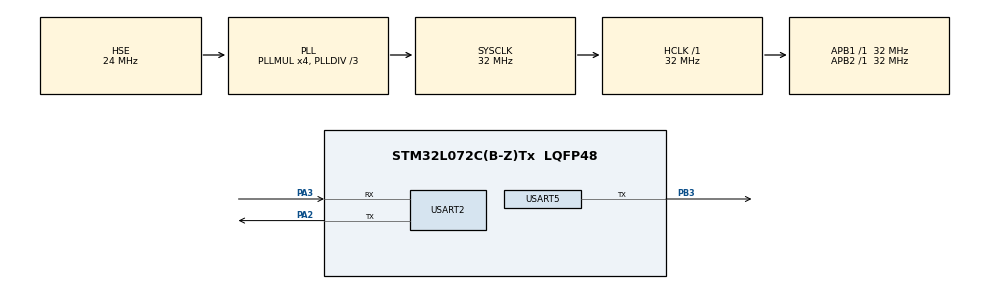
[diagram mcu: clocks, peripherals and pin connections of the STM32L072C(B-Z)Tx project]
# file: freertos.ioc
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Dma.Request0=USART2_RX
Dma.Request1=USART2_TX
Dma.Request2=USART5_TX
Dma.USART2_RX.0.Direction=DMA_PERIPH_TO_MEMORY
Dma.USART2_RX.0.Instance=DMA1_Channel5
Dma.USART2_RX.0.MemDataAlignment=DMA_MDATAALIGN_BYTE
Dma.USART2_RX.0.MemInc=DMA_MINC_ENABLE
Dma.USART2_RX.0.Mode=DMA_CIRCULAR
Dma.USART2_RX.0.PeriphDataAlignment=DMA_PDATAALIGN_BYTE
Dma.USART2_RX.0.PeriphInc=DMA_PINC_DISABLE
Dma.USART2_RX.0.Priority=DMA_PRIORITY_LOW
Dma.USART2_TX.1.Direction=DMA_MEMORY_TO_PERIPH
Dma.USART2_TX.1.Instance=DMA1_Channel4
Dma.USART2_TX.1.MemDataAlignment=DMA_MDATAALIGN_BYTE
Dma.USART2_TX.1.MemInc=DMA_MINC_ENABLE
Dma.USART2_TX.1.Mode=DMA_NORMAL
Dma.USART2_TX.1.PeriphDataAlignment=DMA_PDATAALIGN_BYTE
Dma.USART2_TX.1.PeriphInc=DMA_PINC_DISABLE
Dma.USART2_TX.1.Priority=DMA_PRIORITY_LOW
Dma.USART5_TX.2.Direction=DMA_MEMORY_TO_PERIPH
Dma.USART5_TX.2.Instance=DMA1_Channel3
Dma.USART5_TX.2.MemDataAlignment=DMA_MDATAALIGN_BYTE
Dma.USART5_TX.2.MemInc=DMA_MINC_ENABLE
Dma.USART5_TX.2.Mode=DMA_NORMAL
Dma.USART5_TX.2.PeriphDataAlignment=DMA_PDATAALIGN_BYTE
Dma.USART5_TX.2.PeriphInc=DMA_PINC_DISABLE
Dma.USART5_TX.2.Priority=DMA_PRIORITY_LOW
FREERTOS.Tasks01=defaultTask,24,128,StartDefaultTask,Default,NULL,Dynamic,NULL,NULL;umodemTask,24,256,StartUmodemTask,Default,NULL,Dynamic,NULL,NULL
FREERTOS.configGENERATE_RUN_TIME_STATS=1
FREERTOS.configRECORD_STACK_HIGH_ADDRESS=1
FREERTOS.configTOTAL_HEAP_SIZE=8192
Mcu.Family=STM32L0
Mcu.Name=STM32L072C(B-Z)Tx
Mcu.Package=LQFP48
NVIC.DMA1_Channel2_3_IRQn=true\:3\:0\:false\:false\:true\:true\:false\:true\:true
NVIC.DMA1_Channel4_5_6_7_IRQn=true\:3\:0\:false\:false\:true\:true\:false\:true\:true
NVIC.TIM2_IRQn=true\:3\:0\:false\:false\:true\:false\:false\:true\:true
NVIC.TimeBase=TIM2_IRQn
NVIC.TimeBaseIP=TIM2
NVIC.USART2_IRQn=true\:3\:0\:false\:false\:true\:true\:false\:true\:true
NVIC.USART4_5_IRQn=true\:3\:0\:false\:false\:true\:true\:true\:true\:true
PA2.Mode=Asynchronous
PA2.Signal=USART2_TX
PA3.Mode=Asynchronous
PA3.Signal=USART2_RX
PB3.Mode=Half_duplex(single_wire_mode)
PB3.Signal=USART5_TX
PH0-OSC_IN.Mode=HSE-External-Oscillator
PH0-OSC_IN.Signal=RCC_OSC_IN
PH1-OSC_OUT.Mode=HSE-External-Oscillator
PH1-OSC_OUT.Signal=RCC_OSC_OUT
ProjectManager.HeapSize=0x200
ProjectManager.StackSize=0x400
ProjectManager.TargetToolchain=CMake
RCC.AHBFreq_Value=32000000
RCC.APB1Freq_Value=32000000
RCC.APB1TimFreq_Value=32000000
RCC.APB2Freq_Value=32000000
RCC.APB2TimFreq_Value=32000000
RCC.HCLKFreq_Value=32000000
RCC.HSE_VALUE=24000000
RCC.HSI16_VALUE=16000000
RCC.HSI48_VALUE=48000000
RCC.HSI_VALUE=16000000
RCC.LSE_VALUE=32768
RCC.MSI_VALUE=2097000
RCC.PLLDIV=RCC_PLLDIV_3
RCC.PLLMUL=RCC_PLLMUL_4
RCC.PLLSourceVirtual=RCC_PLLSOURCE_HSE
RCC.SYSCLKFreq_VALUE=32000000
RCC.SYSCLKSource=RCC_SYSCLKSOURCE_PLLCLK
RCC.VCOOutputFreq_Value=96000000
USART2.VirtualMode-Asynchronous=VM_ASYNC
USART5.Mode=MODE_TX
USART5.VirtualMode-Half_duplex(single_wire_mode)=VM_ASYNC
VP_FREERTOS_VS_CMSIS_V2.Mode=CMSIS_V2
VP_SYS_VS_tim2.Mode=TIM2
board=custom

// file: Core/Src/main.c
/* USER CODE BEGIN Header */
/**
 ******************************************************************************
 * @file           : main.c
 * @brief          : Main program body
 ******************************************************************************
 * @attention
 *
 * Copyright (c) 2025 STMicroelectronics.
 * All rights reserved.
 *
 * This software is licensed under terms that can be found in the LICENSE file
 * in the root directory of this software component.
 * If no LICENSE file comes with this software, it is provided AS-IS.
 *
 ******************************************************************************
 */
/* USER CODE END Header */
#include "main.h"
#include "cmsis_os.h"

/* USER CODE BEGIN Includes */
#include <stdio.h>
#include <string.h>
#include <stdlib.h>

#include "umodem.h"
#include "umodem_sock.h"
/* USER CODE END Includes */

UART_HandleTypeDef huart2;
UART_HandleTypeDef huart5;
DMA_HandleTypeDef hdma_usart2_rx;
DMA_HandleTypeDef hdma_usart2_tx;
DMA_HandleTypeDef hdma_usart5_tx;

/* Definitions for defaultTask */
osThreadId_t defaultTaskHandle;
const osThreadAttr_t defaultTask_attributes = {
  .name = "defaultTask",
  .stack_size = 128 * 4,
  .priority = (osPriority_t) osPriorityNormal,
};
/* Definitions for umodemTask */
osThreadId_t umodemTaskHandle;
const osThreadAttr_t umodemTask_attributes = {
  .name = "umodemTask",
  .stack_size = 256 * 4,
  .priority = (osPriority_t) osPriorityNormal,
};

void SystemClock_Config(void);
static void MX_GPIO_Init(void);
static void MX_DMA_Init(void);
static void MX_USART2_UART_Init(void);
static void MX_USART5_UART_Init(void);
void StartDefaultTask(void *argument);
void StartUmodemTask(void *argument);

/* USER CODE BEGIN 0 */
static osSemaphoreId_t tx5_sem = NULL;
void HAL_UART5_TxCpltCallback(UART_HandleTypeDef *huart)
{
  if (huart->Instance == USART5)
    osSemaphoreRelease(tx5_sem); /* Release the semaphore after the DMA transfer is complete */
}

#ifdef __GNUC__
/* With GCC/RAISONANCE, small printf (option LD Linker->Libraries->Small printf
   set to 'Yes') calls __io_putchar() */
#define PUTCHAR_PROTOTYPE int __io_putchar(int ch)
#else
#define PUTCHAR_PROTOTYPE int fputc(int ch, FILE *f)
#endif /* __GNUC__ */

PUTCHAR_PROTOTYPE
{
  /* Place your implementation of fputc here */
  /* e.g. write a character to the USART5 and Loop until the end of transmission */
  osSemaphoreAcquire(tx5_sem, osWaitForever);
  HAL_UART_Transmit_DMA(&huart5, (uint8_t *)&ch, 1);

  return ch;
}
/* USER CODE END 0 */

int main(void)
{

  /* MCU Configuration--------------------------------------------------------*/

  /* Reset of all peripherals, Initializes the Flash interface and the Systick. */
  HAL_Init();

  /* Configure the system clock */
  SystemClock_Config();

  /* Initialize all configured peripherals */
  MX_GPIO_Init();
  MX_DMA_Init();
  MX_USART2_UART_Init();
  MX_USART5_UART_Init();

  /* Init scheduler */
  osKernelInitialize();

  /* Create the thread(s) */
  /* creation of defaultTask */
  defaultTaskHandle = osThreadNew(StartDefaultTask, NULL, &defaultTask_attributes);

  /* creation of umodemTask */
  umodemTaskHandle = osThreadNew(StartUmodemTask, NULL, &umodemTask_attributes);

  /* Start scheduler */
  osKernelStart();

  /* We should never get here as control is now taken by the scheduler */

  /* Infinite loop */
  while (1)
  {

  }
}

void SystemClock_Config(void)
{
  RCC_OscInitTypeDef RCC_OscInitStruct = {0};
  RCC_ClkInitTypeDef RCC_ClkInitStruct = {0};
  RCC_PeriphCLKInitTypeDef PeriphClkInit = {0};

  /** Configure the main internal regulator output voltage
  */
  __HAL_PWR_VOLTAGESCALING_CONFIG(PWR_REGULATOR_VOLTAGE_SCALE1);

  /** Initializes the RCC Oscillators according to the specified parameters
  * in the RCC_OscInitTypeDef structure.
  */
  RCC_OscInitStruct.OscillatorType = RCC_OSCILLATORTYPE_HSE;
  RCC_OscInitStruct.HSEState = RCC_HSE_ON;
  RCC_OscInitStruct.PLL.PLLState = RCC_PLL_ON;
  RCC_OscInitStruct.PLL.PLLSource = RCC_PLLSOURCE_HSE;
  RCC_OscInitStruct.PLL.PLLMUL = RCC_PLLMUL_4;
  RCC_OscInitStruct.PLL.PLLDIV = RCC_PLLDIV_3;
  if (HAL_RCC_OscConfig(&RCC_OscInitStruct) != HAL_OK)
  {
    Error_Handler();
  }

  /** Initializes the CPU, AHB and APB buses clocks
  */
  RCC_ClkInitStruct.ClockType = RCC_CLOCKTYPE_HCLK|RCC_CLOCKTYPE_SYSCLK
                              |RCC_CLOCKTYPE_PCLK1|RCC_CLOCKTYPE_PCLK2;
  RCC_ClkInitStruct.SYSCLKSource = RCC_SYSCLKSOURCE_PLLCLK;
  RCC_ClkInitStruct.AHBCLKDivider = RCC_SYSCLK_DIV1;
  RCC_ClkInitStruct.APB1CLKDivider = RCC_HCLK_DIV1;
  RCC_ClkInitStruct.APB2CLKDivider = RCC_HCLK_DIV1;

  if (HAL_RCC_ClockConfig(&RCC_ClkInitStruct, FLASH_LATENCY_1) != HAL_OK)
  {
    Error_Handler();
  }
  PeriphClkInit.PeriphClockSelection = RCC_PERIPHCLK_USART2;
  PeriphClkInit.Usart2ClockSelection = RCC_USART2CLKSOURCE_PCLK1;
  if (HAL_RCCEx_PeriphCLKConfig(&PeriphClkInit) != HAL_OK)
  {
    Error_Handler();
  }
}

static void MX_USART2_UART_Init(void)
{

  huart2.Instance = USART2;
  huart2.Init.BaudRate = 115200;
  huart2.Init.WordLength = UART_WORDLENGTH_8B;
  huart2.Init.StopBits = UART_STOPBITS_1;
  huart2.Init.Parity = UART_PARITY_NONE;
  huart2.Init.Mode = UART_MODE_TX_RX;
  huart2.Init.HwFlowCtl = UART_HWCONTROL_NONE;
  huart2.Init.OverSampling = UART_OVERSAMPLING_16;
  huart2.Init.OneBitSampling = UART_ONE_BIT_SAMPLE_DISABLE;
  huart2.AdvancedInit.AdvFeatureInit = UART_ADVFEATURE_NO_INIT;
  if (HAL_UART_Init(&huart2) != HAL_OK)
  {
    Error_Handler();
  }

}

static void MX_USART5_UART_Init(void)
{

  /* USER CODE BEGIN USART5_Init 0 */
  tx5_sem = osSemaphoreNew(1, 1, NULL);
  if (tx5_sem == NULL)
  {
    Error_Handler();
  }
  /* USER CODE END USART5_Init 0 */

  huart5.Instance = USART5;
  huart5.Init.BaudRate = 115200;
  huart5.Init.WordLength = UART_WORDLENGTH_8B;
  huart5.Init.StopBits = UART_STOPBITS_1;
  huart5.Init.Parity = UART_PARITY_NONE;
  huart5.Init.Mode = UART_MODE_TX;
  huart5.Init.HwFlowCtl = UART_HWCONTROL_NONE;
  huart5.Init.OverSampling = UART_OVERSAMPLING_16;
  huart5.Init.OneBitSampling = UART_ONE_BIT_SAMPLE_DISABLE;
  huart5.AdvancedInit.AdvFeatureInit = UART_ADVFEATURE_NO_INIT;
  if (HAL_HalfDuplex_Init(&huart5) != HAL_OK)
  {
    Error_Handler();
  }
  /* USER CODE BEGIN USART5_Init 2 */
  if (HAL_UART_RegisterCallback(&huart5, HAL_UART_TX_COMPLETE_CB_ID, HAL_UART5_TxCpltCallback) != HAL_OK)
  {
    Error_Handler();
  }
  /* USER CODE END USART5_Init 2 */

}

static void MX_DMA_Init(void)
{

  /* DMA controller clock enable */
  __HAL_RCC_DMA1_CLK_ENABLE();

  /* DMA interrupt init */
  /* DMA1_Channel2_3_IRQn interrupt configuration */
  HAL_NVIC_SetPriority(DMA1_Channel2_3_IRQn, 3, 0);
  HAL_NVIC_EnableIRQ(DMA1_Channel2_3_IRQn);
  /* DMA1_Channel4_5_6_7_IRQn interrupt configuration */
  HAL_NVIC_SetPriority(DMA1_Channel4_5_6_7_IRQn, 3, 0);
  HAL_NVIC_EnableIRQ(DMA1_Channel4_5_6_7_IRQn);

}

static void MX_GPIO_Init(void)
{

  /* GPIO Ports Clock Enable */
  __HAL_RCC_GPIOH_CLK_ENABLE();
  __HAL_RCC_GPIOA_CLK_ENABLE();
  __HAL_RCC_GPIOB_CLK_ENABLE();

}

void StartDefaultTask(void *argument)
{
  for (;;)
  {
    osDelay(1);
  }
}

/* USER CODE BEGIN Header_StartUmodemTask */
/**
 * @brief Function implementing the umodemTask thread.
 * @param argument: Not used
 * @retval None
 */
static void on_umodem_event(umodem_event_t *event, void *user_ctx)
{
  umodem_event_flag_t event_flag = umodem_event_get_flag(event);
  switch (event_flag)
  {
  case UMODEM_EVENT_SOCK_CONNECTED: {
    void *event_data = umodem_get_event_data(event);
    printf("Socket connected! on fd %d\n", *(int *)event_data);
    break;
  }
  case UMODEM_EVENT_SOCK_DATA_RECEIVED:
  {
    void *event_data = umodem_get_event_data(event);
    printf("Socket data received on fd %d\n", *(int *)event_data);

    // Read data
    char *buf = (char *)pvPortMalloc(128);
    memset(buf, 0, 128);
    if (buf == NULL)
    {
      printf("Memory allocation failed\n");
      return;
    }

    int len = umodem_sock_recv(*(int *)event_data, buf, 128 - 1);
    if (len > 0)
    {
      buf[len] = '\0';
      printf("Received data (%d bytes): %s\n", len, buf);
    }
    else
      printf("Receive error or no data\n");
    vPortFree(buf);
    break;
  }
  case UMODEM_EVENT_SOCK_CLOSED:
    printf("Socket closed\n");
    break;
  default:
    break;
  }
}

static umodem_apn_t apn = {
    .apn = "internet",
    .user = "",
    .pass = "",
};
static char imei[16];
static char iccid[24];
static int rssi = 0, ber = 0;
/* USER CODE END Header_StartUmodemTask */
void StartUmodemTask(void *argument)
{
  /* USER CODE BEGIN StartUmodemTask */
  if (umodem_power_on() != UMODEM_OK)
    Error_Handler();

  if (umodem_init(&apn) != UMODEM_OK)
  {
    printf("Failed to initialize uModem\n");
    umodem_power_off();
    Error_Handler();
  }

  printf("uModem Initialized\n");

  umodem_register_event_callback(on_umodem_event, NULL);

  if (umodem_get_imei(imei, sizeof(imei)) == UMODEM_OK)
    printf("IMEI: %s\n", imei);

  osDelay(pdMS_TO_TICKS(2000)); // wait a bit for signal quality to stabilize

  if (umodem_get_signal_quality(&rssi, &ber) == UMODEM_OK)
    printf("Signal Quality: RSSI=%d, BER=%d\n", rssi, ber);

  if (umodem_get_iccid(iccid, sizeof(iccid)) == UMODEM_OK)
    printf("ICCID: %s\n", iccid);

  int sockfd = -1;
  const char host[] = "tcpbin.com";
  uint16_t port = 4242;

  if (umodem_sock_init() != UMODEM_OK)
  {
    printf("Failed to initialize socket\n");
    Error_Handler();
  }

  sockfd = umodem_sock_create(UMODEM_SOCK_TCP);
  if (sockfd < 0)
  {
    printf("Failed to create socket\n");
    Error_Handler();
  }

  printf("Socket created with fd: %d\n", sockfd);

  if (umodem_sock_connect(sockfd, host, sizeof(host) - 1, port, 10000) == UMODEM_OK)
  {
    // Send data
    const char *msg = "Hello from uModem!\n";
    if (umodem_sock_send(sockfd, (uint8_t *)msg, strlen(msg)) > 0)
      printf("Data sent\n");
    else
      printf("Send failed\n");
  }
  else
    printf("Connect command failed\n");

  /* Infinite loop */
  for (;;)
  {
    umodem_poll();
    osDelay(1);
  }
  /* USER CODE END StartUmodemTask */
}

void HAL_TIM_PeriodElapsedCallback(TIM_HandleTypeDef *htim)
{
  if (htim->Instance == TIM2)
  {
    HAL_IncTick();
  }
}

void Error_Handler(void)
{
  __disable_irq();
  while (1)
  {
  }
}
